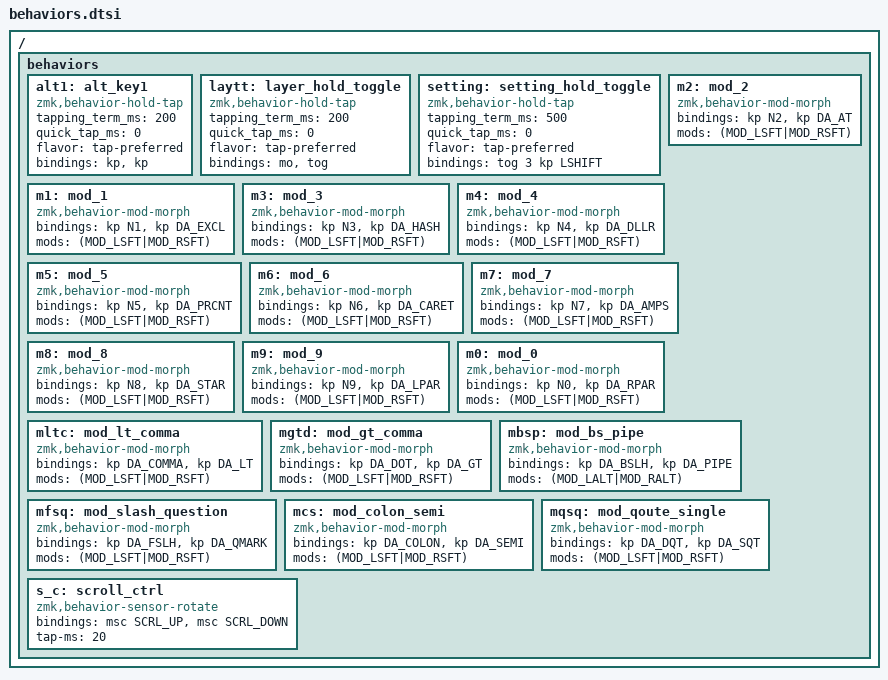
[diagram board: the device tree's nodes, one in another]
/ {
    behaviors {
        alt1: alt_key1 {
            compatible = "zmk,behavior-hold-tap";
            #binding-cells = <2>;
            tapping_term_ms = <200>;
            quick_tap_ms = <0>;
            flavor = "tap-preferred";
            bindings = <&kp>, <&kp>;
        };
        laytt: layer_hold_toggle {
            compatible = "zmk,behavior-hold-tap";
            #binding-cells = <2>;
            tapping_term_ms = <200>;
            quick_tap_ms = <0>;
            flavor = "tap-preferred";
            bindings = <&mo>, <&tog>;
        };
        setting: setting_hold_toggle {
            compatible = "zmk,behavior-hold-tap";
            #binding-cells = <0>;
            tapping_term_ms = <500>;
            quick_tap_ms = <0>;
            flavor = "tap-preferred";
            bindings = <&tog 3 kp LSHIFT>;
        };

        m1: mod_1 {
            compatible = "zmk,behavior-mod-morph";
            #binding-cells = <0>;
            bindings = <&kp N1>, <&kp DA_EXCL>;
            mods = <(MOD_LSFT|MOD_RSFT)>;
        };

        m2: mod_2 {
            compatible = "zmk,behavior-mod-morph";
            #binding-cells = <0>;
            bindings = <&kp N2>, <&kp DA_AT>;
            mods = <(MOD_LSFT|MOD_RSFT)>;
        };

        m3: mod_3 {
            compatible = "zmk,behavior-mod-morph";
            #binding-cells = <0>;
            bindings = <&kp N3>, <&kp DA_HASH>;
            mods = <(MOD_LSFT|MOD_RSFT)>;
        };

        m4: mod_4 {
            compatible = "zmk,behavior-mod-morph";
            #binding-cells = <0>;
            bindings = <&kp N4>, <&kp DA_DLLR>;
            mods = <(MOD_LSFT|MOD_RSFT)>;
        };

        m5: mod_5 {
            compatible = "zmk,behavior-mod-morph";
            #binding-cells = <0>;
            bindings = <&kp N5>, <&kp DA_PRCNT>;
            mods = <(MOD_LSFT|MOD_RSFT)>;
        };

        m6: mod_6 {
            compatible = "zmk,behavior-mod-morph";
            #binding-cells = <0>;
            bindings = <&kp N6>, <&kp DA_CARET>;
            mods = <(MOD_LSFT|MOD_RSFT)>;
        };

        m7: mod_7 {
            compatible = "zmk,behavior-mod-morph";
            #binding-cells = <0>;
            bindings = <&kp N7>, <&kp DA_AMPS>;
            mods = <(MOD_LSFT|MOD_RSFT)>;
        };

        m8: mod_8 {
            compatible = "zmk,behavior-mod-morph";
            #binding-cells = <0>;
            bindings = <&kp N8>, <&kp DA_STAR>;  
            mods = <(MOD_LSFT|MOD_RSFT)>;
        };

        m9: mod_9 {
            compatible = "zmk,behavior-mod-morph";
            #binding-cells = <0>;
            bindings = <&kp N9>, <&kp DA_LPAR>; 
            mods = <(MOD_LSFT|MOD_RSFT)>;
        };
   
        m0: mod_0 {
            compatible = "zmk,behavior-mod-morph";
            #binding-cells = <0>;
            bindings = <&kp N0>, <&kp DA_RPAR>; 
            mods = <(MOD_LSFT|MOD_RSFT)>;
        };
        mltc: mod_lt_comma {
            compatible = "zmk,behavior-mod-morph";
            #binding-cells = <0>;
            bindings = <&kp DA_COMMA>, <&kp DA_LT>; 
            mods = <(MOD_LSFT|MOD_RSFT)>;
        };
        mgtd: mod_gt_comma {
            compatible = "zmk,behavior-mod-morph";
            #binding-cells = <0>;
            bindings = <&kp DA_DOT>, <&kp DA_GT>; 
            mods = <(MOD_LSFT|MOD_RSFT)>;
        };
        mbsp: mod_bs_pipe {
            compatible = "zmk,behavior-mod-morph";
            #binding-cells = <0>;
            bindings = <&kp DA_BSLH>, <&kp DA_PIPE>; 
            mods = <(MOD_LALT|MOD_RALT)>;
        };
        mfsq: mod_slash_question {
            compatible = "zmk,behavior-mod-morph";
            #binding-cells = <0>;
            bindings = <&kp DA_FSLH>, <&kp DA_QMARK>; 
            mods = <(MOD_LSFT|MOD_RSFT)>;
        };
        mcs: mod_colon_semi {
            compatible = "zmk,behavior-mod-morph";
            #binding-cells = <0>;
            bindings = <&kp DA_COLON>, <&kp DA_SEMI>; 
            mods = <(MOD_LSFT|MOD_RSFT)>;
        };
        mqsq: mod_qoute_single {
            compatible = "zmk,behavior-mod-morph";
            #binding-cells = <0>;
            bindings = <&kp DA_DQT>, <&kp DA_SQT>; 
            mods = <(MOD_LSFT|MOD_RSFT)>;
        };

        // sensors
        s_c: scroll_ctrl {
            compatible = "zmk,behavior-sensor-rotate";
            #sensor-binding-cells = <0>;
            bindings = <&msc SCRL_UP>, <&msc SCRL_DOWN>;
            tap-ms = <20>;
        };
    };
};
